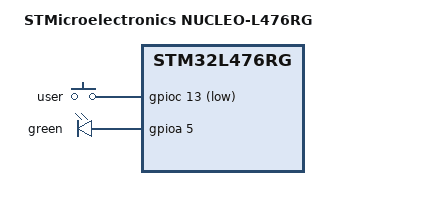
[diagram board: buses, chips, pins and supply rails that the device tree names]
/**
 * \file
 * \brief Devicetree for NUCLEO-L476RG
 *
 * \author Copyright (C) 2017 Kamil Szczygiel http://www.distortec.com http://www.freddiechopin.info
 *
 * \par License
 * This Source Code Form is subject to the terms of the Mozilla Public License, v. 2.0. If a copy of the MPL was not
 * distributed with this file, You can obtain one at http://mozilla.org/MPL/2.0/.
 */

/dts-v1/;

#include "STM32L476RG.dtsi"

/ {
	compatible = "ST,NUCLEO-L476RG", "ST,STM32L476RG";
	model = "STMicroelectronics NUCLEO-L476RG";

	buttons {
		compatible = "gpio-keys";
		status = "okay";

		b1 {
			gpios = <&gpioc 13 1>;
			label = "user";
			status = "okay";
		};
	};

	leds {
		compatible = "gpio-leds";
		status = "okay";

		ld2 {
			gpios = <&gpioa 5 0>;
			label = "green";
			status = "okay";
		};
	};
};

&gpioa {
	status = "okay";
};

&gpioc {
	status = "okay";
};
